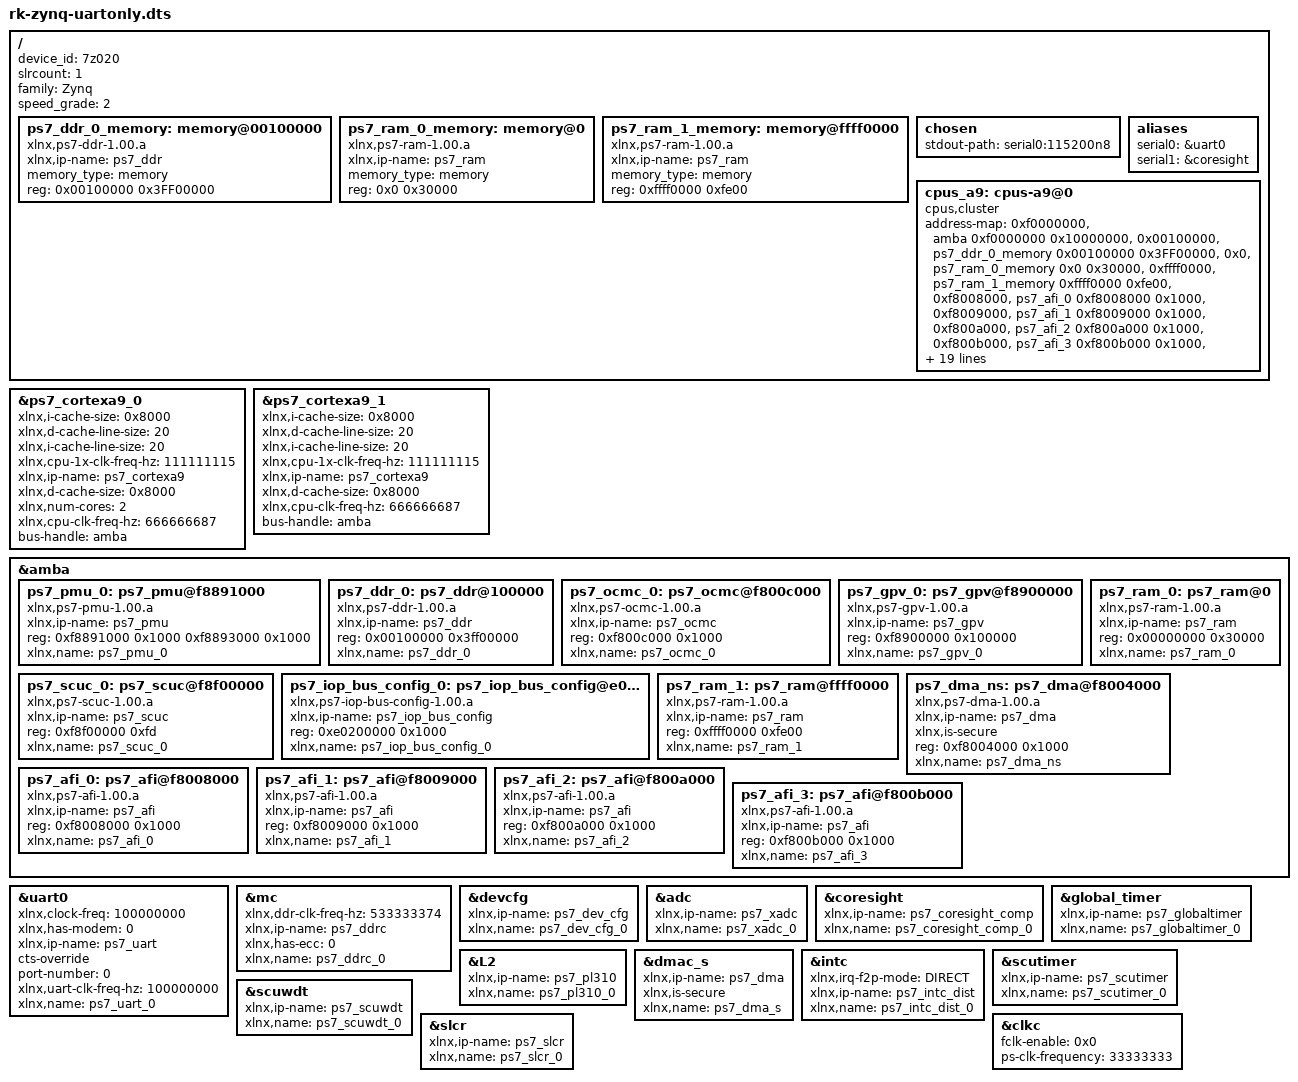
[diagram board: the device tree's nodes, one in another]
/dts-v1/;
#include "zynq-7000.dtsi"
&ps7_cortexa9_0 {
	xlnx,i-cache-size = <0x8000>;
	xlnx,d-cache-line-size = <20>;
	xlnx,i-cache-line-size = <20>;
	xlnx,cpu-1x-clk-freq-hz = <111111115>;
	xlnx,ip-name = "ps7_cortexa9";
	xlnx,d-cache-size = <0x8000>;
	xlnx,num-cores = <2>;
	xlnx,cpu-clk-freq-hz = <666666687>;
	bus-handle = <&amba>;
};
&ps7_cortexa9_1 {
	xlnx,i-cache-size = <0x8000>;
	xlnx,d-cache-line-size = <20>;
	xlnx,i-cache-line-size = <20>;
	xlnx,cpu-1x-clk-freq-hz = <111111115>;
	xlnx,ip-name = "ps7_cortexa9";
	xlnx,d-cache-size = <0x8000>;
	xlnx,cpu-clk-freq-hz = <666666687>;
	bus-handle = <&amba>;
};
&amba {
	ps7_pmu_0: ps7_pmu@f8891000 {
		compatible = "xlnx,ps7-pmu-1.00.a";
		status = "okay";
		xlnx,ip-name = "ps7_pmu";
		reg = <0xf8891000 0x1000 0xf8893000 0x1000>;
		xlnx,name = "ps7_pmu_0";
	};
	ps7_ddr_0: ps7_ddr@100000 {
		compatible = "xlnx,ps7-ddr-1.00.a";
		status = "okay";
		xlnx,ip-name = "ps7_ddr";
		reg = <0x00100000 0x3ff00000>;
		xlnx,name = "ps7_ddr_0";
	};
	ps7_ocmc_0: ps7_ocmc@f800c000 {
		compatible = "xlnx,ps7-ocmc-1.00.a";
		status = "okay";
		xlnx,ip-name = "ps7_ocmc";
		reg = <0xf800c000 0x1000>;
		xlnx,name = "ps7_ocmc_0";
	};
	ps7_gpv_0: ps7_gpv@f8900000 {
		compatible = "xlnx,ps7-gpv-1.00.a";
		status = "okay";
		xlnx,ip-name = "ps7_gpv";
		reg = <0xf8900000 0x100000>;
		xlnx,name = "ps7_gpv_0";
	};
	ps7_scuc_0: ps7_scuc@f8f00000 {
		compatible = "xlnx,ps7-scuc-1.00.a";
		status = "okay";
		xlnx,ip-name = "ps7_scuc";
		reg = <0xf8f00000 0xfd>;
		xlnx,name = "ps7_scuc_0";
		};
	ps7_iop_bus_config_0: ps7_iop_bus_config@e0200000 {
		compatible = "xlnx,ps7-iop-bus-config-1.00.a";
		status = "okay";
		xlnx,ip-name = "ps7_iop_bus_config";
		reg = <0xe0200000 0x1000>;
		xlnx,name = "ps7_iop_bus_config_0";
	};
	ps7_ram_0: ps7_ram@0 {
		compatible = "xlnx,ps7-ram-1.00.a";
		status = "okay";
		xlnx,ip-name = "ps7_ram";
		reg = <0x00000000 0x30000>;
		xlnx,name = "ps7_ram_0";
	};
	ps7_ram_1: ps7_ram@ffff0000 {
		compatible = "xlnx,ps7-ram-1.00.a";
		status = "okay";
		xlnx,ip-name = "ps7_ram";
		reg = <0xffff0000 0xfe00>;
		xlnx,name = "ps7_ram_1";
	};
	ps7_dma_ns: ps7_dma@f8004000 {
		compatible = "xlnx,ps7-dma-1.00.a";
		status = "okay";
		xlnx,ip-name = "ps7_dma";
			xlnx,is-secure;
			reg = <0xf8004000 0x1000>;
			xlnx,name = "ps7_dma_ns";
	};
	ps7_afi_0: ps7_afi@f8008000 {
		compatible = "xlnx,ps7-afi-1.00.a";
		status = "okay";
		xlnx,ip-name = "ps7_afi";
		reg = <0xf8008000 0x1000>;
			xlnx,name = "ps7_afi_0";
	};
	ps7_afi_1: ps7_afi@f8009000 {
		compatible = "xlnx,ps7-afi-1.00.a";
		status = "okay";
		xlnx,ip-name = "ps7_afi";
		reg = <0xf8009000 0x1000>;
		xlnx,name = "ps7_afi_1";
	};
	ps7_afi_2: ps7_afi@f800a000 {
		compatible = "xlnx,ps7-afi-1.00.a";
		status = "okay";
		xlnx,ip-name = "ps7_afi";
		reg = <0xf800a000 0x1000>;
		xlnx,name = "ps7_afi_2";
		};
	ps7_afi_3: ps7_afi@f800b000 {
		compatible = "xlnx,ps7-afi-1.00.a";
		status = "okay";
		xlnx,ip-name = "ps7_afi";
		reg = <0xf800b000 0x1000>;
		xlnx,name = "ps7_afi_3";
	};
};
&uart0 {
	status = "okay";
	xlnx,clock-freq = <100000000>;
	xlnx,has-modem = <0>;
	xlnx,ip-name = "ps7_uart";
	cts-override;
	port-number = <0>;
	xlnx,uart-clk-freq-hz = <100000000>;
	xlnx,name = "ps7_uart_0";
	};
&mc {
	status = "okay";
	xlnx,ddr-clk-freq-hz = <533333374>;
	xlnx,ip-name = "ps7_ddrc";
	xlnx,has-ecc = <0>;
	xlnx,name = "ps7_ddrc_0";
};
&devcfg {
	status = "okay";
	xlnx,ip-name = "ps7_dev_cfg";
	xlnx,name = "ps7_dev_cfg_0";
};
&adc {
	status = "okay";
	xlnx,ip-name = "ps7_xadc";
	xlnx,name = "ps7_xadc_0";
};
&coresight {
	status = "okay";
	xlnx,ip-name = "ps7_coresight_comp";
	xlnx,name = "ps7_coresight_comp_0";
};
&global_timer {
	status = "okay";
	xlnx,ip-name = "ps7_globaltimer";
	xlnx,name = "ps7_globaltimer_0";
};
&L2 {
	status = "okay";
	xlnx,ip-name = "ps7_pl310";
	xlnx,name = "ps7_pl310_0";
};
&dmac_s {
	status = "okay";
	xlnx,ip-name = "ps7_dma";
	xlnx,is-secure;
	xlnx,name = "ps7_dma_s";
};
&intc {
	status = "okay";
	xlnx,irq-f2p-mode = "DIRECT";
	xlnx,ip-name = "ps7_intc_dist";
	xlnx,name = "ps7_intc_dist_0";
};
&scutimer {
	status = "okay";
	xlnx,ip-name = "ps7_scutimer";
	xlnx,name = "ps7_scutimer_0";
};
&scuwdt {
	status = "okay";
	xlnx,ip-name = "ps7_scuwdt";
	xlnx,name = "ps7_scuwdt_0";
};
&slcr {
	status = "okay";
	xlnx,ip-name = "ps7_slcr";
	xlnx,name = "ps7_slcr_0";
};
&clkc {
	fclk-enable = <0x0>;
	ps-clk-frequency = <33333333>;
};
/ {
	device_id = "7z020";
	slrcount = <1>;
	family = "Zynq";
	speed_grade = "2";
	ps7_ddr_0_memory: memory@00100000 {
		compatible = "xlnx,ps7-ddr-1.00.a";
		xlnx,ip-name = "ps7_ddr";
		device_type = "memory";
		memory_type = "memory";
		reg = <0x00100000 0x3FF00000>;
	};
	ps7_ram_0_memory: memory@0 {
		compatible = "xlnx,ps7-ram-1.00.a";
		xlnx,ip-name = "ps7_ram";
		device_type = "memory";
		memory_type = "memory";
		reg = <0x0 0x30000>;
	};
	ps7_ram_1_memory: memory@ffff0000 {
		compatible = "xlnx,ps7-ram-1.00.a";
		xlnx,ip-name = "ps7_ram";
		device_type = "memory";
		memory_type = "memory";
		reg = <0xffff0000 0xfe00>;
	};
	chosen {
		stdout-path = "serial0:115200n8";
	};
	aliases {
		serial0 = &uart0;
		serial1 = &coresight;
	};
	cpus_a9: cpus-a9@0 {
		compatible = "cpus,cluster";
		address-map = <0xf0000000 &amba 0xf0000000 0x10000000>, 
			      <0x00100000 &ps7_ddr_0_memory 0x00100000 0x3FF00000>, 
			      <0x0 &ps7_ram_0_memory 0x0 0x30000>, 
			      <0xffff0000 &ps7_ram_1_memory 0xffff0000 0xfe00>, 
			      <0xf8008000 &ps7_afi_0 0xf8008000 0x1000>, 
			      <0xf8009000 &ps7_afi_1 0xf8009000 0x1000>, 
			      <0xf800a000 &ps7_afi_2 0xf800a000 0x1000>, 
			      <0xf800b000 &ps7_afi_3 0xf800b000 0x1000>, 
			      <0xf8800000 &coresight 0xf8800000 0x100000>, 
			      <0xf8006000 &mc 0xf8006000 0x1000>, 
			      <0xf8007000 &devcfg 0xf8007000 0x100>, 
			      <0xf8004000 &ps7_dma_ns 0xf8004000 0x1000>, 
			      <0xf8003000 &dmac_s 0xf8003000 0x1000>, 
			      <0xf8f00200 &global_timer 0xf8f00200 0x100>, 
			      <0xf8900000 &ps7_gpv_0 0xf8900000 0x100000>, 
			      <0xf8f01000 &intc 0xf8f01000 0x1000>, 
			      <0xe0200000 &ps7_iop_bus_config_0 0xe0200000 0x1000>, 
			      <0xf8f02000 &L2 0xf8f02000 0x1000>, 
			      <0xf800c000 &ps7_ocmc_0 0xf800c000 0x1000>, 
			      <0xf8891000 &ps7_pmu_0 0xf8891000 0x1000>, 
			      <0xf8f00000 &ps7_scuc_0 0xf8f00000 0xfd>, 
			      <0xf8f00600 &scutimer 0xf8f00600 0x20>, 
			      <0xf8f00620 &scuwdt 0xf8f00620 0xe0>, 
			      <0xf8000000 &slcr 0xf8000000 0x1000>, 
			      <0xe0000000 &uart0 0xe0000000 0x1000>, 
			      <0xf8007100 &adc 0xf8007100 0x21>;
		#ranges-address-cells = <0x1>;
		#ranges-size-cells = <0x1>;
	};
};
